AUTOSAR XML (schema 00046)
package /ComponentTypes
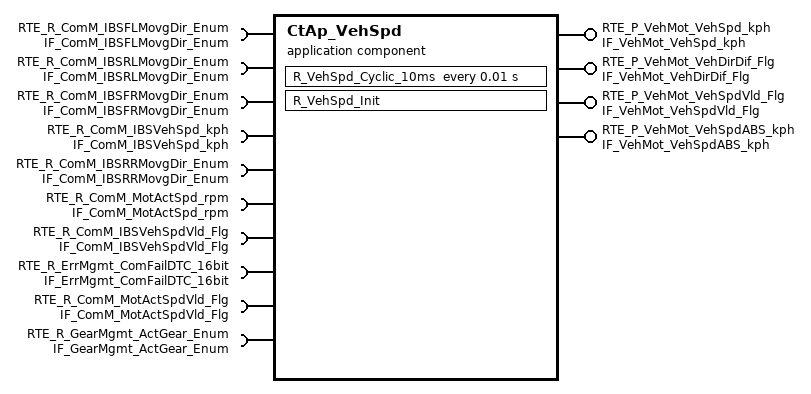
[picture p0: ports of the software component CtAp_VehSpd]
  application sw component type CtAp_VehSpd
    4 x provide port:
      RTE_P_VehMot_VehSpd_kph: nonqueued-sender-com-spec{data-element=tec_VehMot_VehSpd_kph, init-value=0}, provided-interface=IF_VehMot_VehSpd_kph
      RTE_P_VehMot_VehDirDif_Flg: nonqueued-sender-com-spec{data-element=tec_VehMot_VehDirDif_Flg, init-value=0}, provided-interface=IF_VehMot_VehDirDif_Flg
      RTE_P_VehMot_VehSpdVld_Flg: nonqueued-sender-com-spec{data-element=tec_VehMot_VehSpdVld_Flg, init-value=0}, provided-interface=IF_VehMot_VehSpdVld_Flg
      RTE_P_VehMot_VehSpdABS_kph: nonqueued-sender-com-spec{data-element=tec_VehMot_VehSpdABS_kph, init-value=0}, provided-interface=IF_VehMot_VehSpdABS_kph
    10 x require port:
      RTE_R_ComM_IBSFLMovgDir_Enum: nonqueued-receiver-com-spec{data-element=tec_ComM_IBSFLMovgDir_Enum, filter=data-filter-type=ALWAYS, init-value=0}, required-interface=IF_ComM_IBSFLMovgDir_Enum
      RTE_R_ComM_IBSRLMovgDir_Enum: nonqueued-receiver-com-spec{data-element=tec_ComM_IBSRLMovgDir_Enum, filter=data-filter-type=ALWAYS, init-value=0}, required-interface=IF_ComM_IBSRLMovgDir_Enum
      RTE_R_ComM_IBSFRMovgDir_Enum: nonqueued-receiver-com-spec{data-element=tec_ComM_IBSFRMovgDir_Enum, filter=data-filter-type=ALWAYS, init-value=0}, required-interface=IF_ComM_IBSFRMovgDir_Enum
      RTE_R_ComM_IBSVehSpd_kph: nonqueued-receiver-com-spec{data-element=tec_ComM_IBSVehSpd_kph, filter=data-filter-type=ALWAYS, init-value=0}, required-interface=IF_ComM_IBSVehSpd_kph
      RTE_R_ComM_IBSRRMovgDir_Enum: nonqueued-receiver-com-spec{data-element=tec_ComM_IBSRRMovgDir_Enum, filter=data-filter-type=ALWAYS, init-value=0}, required-interface=IF_ComM_IBSRRMovgDir_Enum
      RTE_R_ComM_MotActSpd_rpm: nonqueued-receiver-com-spec{data-element=tec_ComM_MotActSpd_rpm, filter=data-filter-type=ALWAYS, init-value=0}, required-interface=IF_ComM_MotActSpd_rpm
      RTE_R_ComM_IBSVehSpdVld_Flg: nonqueued-receiver-com-spec{data-element=tec_ComM_IBSVehSpdVld_Flg, filter=data-filter-type=ALWAYS, init-value=0}, required-interface=IF_ComM_IBSVehSpdVld_Flg
      RTE_R_ErrMgmt_ComFailDTC_16bit: nonqueued-receiver-com-spec{data-element=tec_ErrMgmt_ComFailDTC_16bit, filter=data-filter-type=ALWAYS, init-value=0}, required-interface=IF_ErrMgmt_ComFailDTC_16bit
      RTE_R_ComM_MotActSpdVld_Flg: nonqueued-receiver-com-spec{data-element=tec_ComM_MotActSpdVld_Flg, filter=data-filter-type=ALWAYS, init-value=0}, required-interface=IF_ComM_MotActSpdVld_Flg
      RTE_R_GearMgmt_ActGear_Enum: nonqueued-receiver-com-spec{data-element=tec_GearMgmt_ActGear_Enum, filter=data-filter-type=ALWAYS, init-value=0}, required-interface=IF_GearMgmt_ActGear_Enum
    behavior CtAp_VehSpd_InternalBehavior
      init event CtAp_VehSpd_InitEvent: start-on-event=R_VehSpd_Init
      timing event TMT_R_VehSpd_Cyclic_10ms: start-on-event=R_VehSpd_Cyclic_10ms, period=0.01
      runnable R_VehSpd_Init
      runnable R_VehSpd_Cyclic_10ms
        data-receive-point-by-arguments:
          10 x access:
            REC_RTE_R_ComM_IBSFLMovgDir_Enum_tec_ComM_IBSFLMovgDir_Enum: accessed-variable=RTE_R_ComM_IBSFLMovgDir_Enum.tec_ComM_IBSFLMovgDir_Enum
            REC_RTE_R_ComM_IBSFRMovgDir_Enum_tec_ComM_IBSFRMovgDir_Enum: accessed-variable=RTE_R_ComM_IBSFRMovgDir_Enum.tec_ComM_IBSFRMovgDir_Enum
            REC_RTE_R_ComM_IBSRLMovgDir_Enum_tec_ComM_IBSRLMovgDir_Enum: accessed-variable=RTE_R_ComM_IBSRLMovgDir_Enum.tec_ComM_IBSRLMovgDir_Enum
            REC_RTE_R_ComM_IBSRRMovgDir_Enum_tec_ComM_IBSRRMovgDir_Enum: accessed-variable=RTE_R_ComM_IBSRRMovgDir_Enum.tec_ComM_IBSRRMovgDir_Enum
            REC_RTE_R_ComM_IBSVehSpdVld_Flg_tec_ComM_IBSVehSpdVld_Flg: accessed-variable=RTE_R_ComM_IBSVehSpdVld_Flg.tec_ComM_IBSVehSpdVld_Flg
            REC_RTE_R_ComM_IBSVehSpd_kph_tec_ComM_IBSVehSpd_kph: accessed-variable=RTE_R_ComM_IBSVehSpd_kph.tec_ComM_IBSVehSpd_kph
            REC_RTE_R_ComM_MotActSpdVld_Flg_tec_ComM_MotActSpdVld_Flg: accessed-variable=RTE_R_ComM_MotActSpdVld_Flg.tec_ComM_MotActSpdVld_Flg
            REC_RTE_R_ComM_MotActSpd_rpm_tec_ComM_MotActSpd_rpm: accessed-variable=RTE_R_ComM_MotActSpd_rpm.tec_ComM_MotActSpd_rpm
            REC_RTE_R_ErrMgmt_ComFailDTC_16bit_tec_ErrMgmt_ComFailDTC_16bit: accessed-variable=RTE_R_ErrMgmt_ComFailDTC_16bit.tec_ErrMgmt_ComFailDTC_16bit
            REC_RTE_R_GearMgmt_ActGear_Enum_tec_GearMgmt_ActGear_Enum: accessed-variable=RTE_R_GearMgmt_ActGear_Enum.tec_GearMgmt_ActGear_Enum
        data-send-points:
          4 x access:
            SEND_RTE_P_VehMot_VehDirDif_Flg_tec_VehMot_VehDirDif_Flg: accessed-variable=RTE_P_VehMot_VehDirDif_Flg.tec_VehMot_VehDirDif_Flg
            SEND_RTE_P_VehMot_VehSpdABS_kph_tec_VehMot_VehSpdABS_kph: accessed-variable=RTE_P_VehMot_VehSpdABS_kph.tec_VehMot_VehSpdABS_kph
            SEND_RTE_P_VehMot_VehSpdVld_Flg_tec_VehMot_VehSpdVld_Flg: accessed-variable=RTE_P_VehMot_VehSpdVld_Flg.tec_VehMot_VehSpdVld_Flg
            SEND_RTE_P_VehMot_VehSpd_kph_tec_VehMot_VehSpd_kph: accessed-variable=RTE_P_VehMot_VehSpd_kph.tec_VehMot_VehSpd_kph
  swc implementation CtAp_VehSpd_Implementation: behavior=CtAp_VehSpd_InternalBehavior
    code-descriptors:
      code Default: artifact-descriptors=autosar-engineering-object=category=SWOBJ
